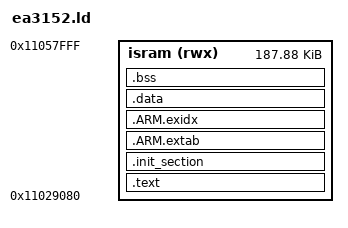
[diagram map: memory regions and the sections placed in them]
/****************************************************************************
 * boards/arm/lpc31xx/ea3152/scripts/ea3152.ld
 *
 * Licensed to the Apache Software Foundation (ASF) under one or more
 * contributor license agreements.  See the NOTICE file distributed with
 * this work for additional information regarding copyright ownership.  The
 * ASF licenses this file to you under the Apache License, Version 2.0 (the
 * "License"); you may not use this file except in compliance with the
 * License.  You may obtain a copy of the License at
 *
 *   http://www.apache.org/licenses/LICENSE-2.0
 *
 * Unless required by applicable law or agreed to in writing, software
 * distributed under the License is distributed on an "AS IS" BASIS, WITHOUT
 * WARRANTIES OR CONDITIONS OF ANY KIND, either express or implied.  See the
 * License for the specific language governing permissions and limitations
 * under the License.
 *
 ****************************************************************************/

/* The LPC3152 has 192Kb of ISRAM beginning at virtual address 0x1102:8000.
 * LPC31xx boot ROM expects the boot image be compiled with entry point at
 * 0x1102:9000.  A 128b header will appear at this address (applied by
 * lpc313xImgCreator) and the executable code must begin at 0x1102:9080.
 */

MEMORY
{
    isram (rwx) : ORIGIN = 0x11029080, LENGTH = 192K - 4224
}

OUTPUT_ARCH(arm)
ENTRY(_stext)
SECTIONS
{
    .text : {
        _stext = ABSOLUTE(.);
        *(.vectors)
        *(.text .text.*)
        *(.fixup)
        *(.gnu.warning)
        *(.rodata .rodata.*)
        *(.gnu.linkonce.t.*)
        *(.glue_7)
        *(.glue_7t)
        *(.got)
        *(.gcc_except_table)
        *(.gnu.linkonce.r.*)
        _etext = ABSOLUTE(.);
    } > isram

    .init_section : {
        _sinit = ABSOLUTE(.);
        *(.init_array .init_array.*)
        _einit = ABSOLUTE(.);
    } > isram

    .ARM.extab : {
        *(.ARM.extab*)
    } > isram

    __exidx_start = ABSOLUTE(.);
    .ARM.exidx : {
        *(.ARM.exidx*)
    } > isram
    __exidx_end = ABSOLUTE(.);

    _eronly = ABSOLUTE(.);

    .data : {
        _sdata = ABSOLUTE(.);
        *(.data .data.*)
        *(.gnu.linkonce.d.*)
        CONSTRUCTORS
        . = ALIGN(4);
        _edata = ABSOLUTE(.);
    } > isram

    .bss : {
        _sbss = ABSOLUTE(.);
        *(.bss .bss.*)
        *(.gnu.linkonce.b.*)
        *(COMMON)
        . = ALIGN(4);
        _ebss = ABSOLUTE(.);
    } > isram
    /* Stabs debugging sections.    */
    .stab 0 : { *(.stab) }
    .stabstr 0 : { *(.stabstr) }
    .stab.excl 0 : { *(.stab.excl) }
    .stab.exclstr 0 : { *(.stab.exclstr) }
    .stab.index 0 : { *(.stab.index) }
    .stab.indexstr 0 : { *(.stab.indexstr) }
    .comment 0 : { *(.comment) }
    .debug_abbrev 0 : { *(.debug_abbrev) }
    .debug_info 0 : { *(.debug_info) }
    .debug_line 0 : { *(.debug_line) }
    .debug_pubnames 0 : { *(.debug_pubnames) }
    .debug_aranges 0 : { *(.debug_aranges) }
}
